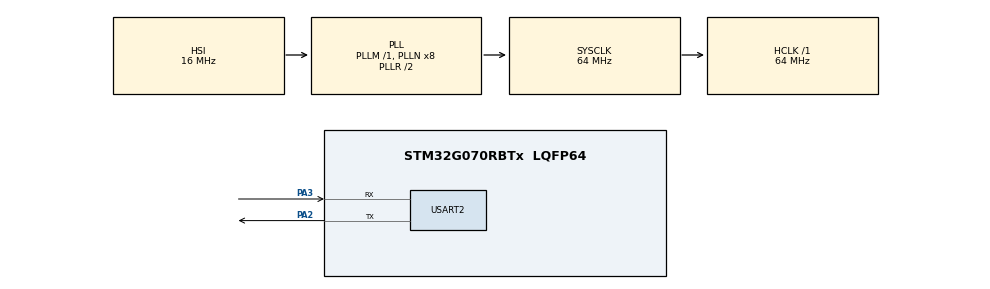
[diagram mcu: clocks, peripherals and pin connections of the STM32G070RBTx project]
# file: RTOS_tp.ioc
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FREERTOS.Tasks01=defaultTask,24,128,StartDefaultTask,Default,NULL,Dynamic,NULL,NULL
FREERTOS.configCHECK_FOR_STACK_OVERFLOW=2
FREERTOS.configTOTAL_HEAP_SIZE=12288
FREERTOS.configUSE_MALLOC_FAILED_HOOK=1
Mcu.Family=STM32G0
Mcu.Name=STM32G070RBTx
Mcu.Package=LQFP64
NVIC.TIM6_IRQn=true\:3\:0\:false\:false\:true\:false\:false\:true\:true
NVIC.TimeBase=TIM6_IRQn
NVIC.TimeBaseIP=TIM6
NVIC.USART2_IRQn=true\:3\:0\:false\:false\:true\:true\:true\:true\:true
PA2.Mode=Asynchronous
PA2.Signal=USART2_TX
PA3.Mode=Asynchronous
PA3.Signal=USART2_RX
PF0-OSC_IN\ (PF0).Mode=HSE-External-Oscillator
PF0-OSC_IN\ (PF0).Signal=RCC_OSC_IN
PF1-OSC_OUT\ (PF1).Mode=HSE-External-Oscillator
PF1-OSC_OUT\ (PF1).Signal=RCC_OSC_OUT
ProjectManager.HeapSize=0x200
ProjectManager.StackSize=0x400
ProjectManager.TargetToolchain=STM32CubeIDE
RCC.ADCFreq_Value=64000000
RCC.AHBFreq_Value=64000000
RCC.CortexFreq_Value=64000000
RCC.EXTERNAL_CLOCK_VALUE=12288000
RCC.HCLKFreq_Value=64000000
RCC.HSE_VALUE=8000000
RCC.HSI_VALUE=16000000
RCC.SYSCLKFreq_VALUE=64000000
RCC.SYSCLKSource=RCC_SYSCLKSOURCE_PLLCLK
RCC.VCOOutputFreq_Value=128000000
USART2.VirtualMode-Asynchronous=VM_ASYNC
VP_FREERTOS_VS_CMSIS_V2.Mode=CMSIS_V2
VP_SYS_VS_tim6.Mode=TIM6
board=NUCLEO-G070RB

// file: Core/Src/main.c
/* USER CODE BEGIN Header */
/**
  ******************************************************************************
  * @file           : main.c
  * @brief          : Main program body
  ******************************************************************************
  * @attention
  *
  * Copyright (c) 2026 STMicroelectronics.
  * All rights reserved.
  *
  * This software is licensed under terms that can be found in the LICENSE file
  * in the root directory of this software component.
  * If no LICENSE file comes with this software, it is provided AS-IS.
  *
  ******************************************************************************
  */
/* USER CODE END Header */
#include "main.h"
#include "cmsis_os.h"

/* USER CODE BEGIN Includes */
/* USER CODE BEGIN Includes */
#include "FreeRTOS.h"
#include "task.h"
#include "queue.h"
#include "semphr.h"
#include <stdio.h>
#include <stdarg.h>
#include <string.h>
#include <stdlib.h>
#include <ctype.h>
/* USER CODE END Includes */

/* USER CODE BEGIN PTD */
/* USER CODE BEGIN PTD */
typedef enum { LED_MODE_OFF, LED_MODE_ON, LED_MODE_BLINK } LedMode_t;

typedef struct {
    LedMode_t mode;
    uint32_t  period_ms;
} LedCmd_t;

typedef struct {
    uint32_t cmds_ok;
    uint32_t cmds_err;
    uint32_t jobs_done;
} Stats_t;

typedef struct {
    const char *name;
    int (*fn)(int argc, char **argv);   /* return 0 = OK, -1 = error */
    const char *help;
} Command_t;
/* USER CODE END PTD */

/* USER CODE BEGIN PD */
/* USER CODE BEGIN PD */
#define LED_PORT        GPIOA
#define LED_PIN         GPIO_PIN_5

/* Task priorities (higher number = higher priority) */
#define PRIO_WORKER     1
#define PRIO_LED        2
#define PRIO_CMD        3

/* Stack sizes in WORDS (4 bytes) */
#define STACK_CMD       384
#define STACK_LED       128
#define STACK_WORKER    384

#define RX_QUEUE_LEN    64
#define LED_QUEUE_LEN   4
#define JOB_POOL_MAX    5      /* counting semaphore max count (N) */
#define CMD_BUF_LEN     64
#define CMD_MAX_ARGS    4
#define TX_BUF_LEN      128
#define NELEMS(a)       (sizeof(a) / sizeof((a)[0]))
/* USER CODE END PD */

UART_HandleTypeDef huart2;

/* Definitions for defaultTask */
osThreadId_t defaultTaskHandle;
const osThreadAttr_t defaultTask_attributes = {
  .name = "defaultTask",
  .priority = (osPriority_t) osPriorityNormal,
  .stack_size = 128 * 4
};
/* USER CODE BEGIN PV */
/* USER CODE BEGIN PV */
QueueHandle_t     qRxBytes;     /* used from it.c (extern) */
QueueHandle_t     qLed;
SemaphoreHandle_t mtxUart;      /* mutex: UART TX */
SemaphoreHandle_t mtxData;      /* mutex: shared stats */
SemaphoreHandle_t semTxDone;    /* binary semaphore (given from ISR) */
SemaphoreHandle_t semJobs;      /* counting semaphore (given from ISR + task) */
TaskHandle_t      hCmdTask, hLedTask, hWorkerTask;

uint8_t rx_byte;                /* single-byte buffer for HAL_UART_Receive_IT */
static Stats_t g_stats;
/* USER CODE END PV */

void SystemClock_Config(void);
static void MX_GPIO_Init(void);
static void MX_USART2_UART_Init(void);
void StartDefaultTask(void *argument);

/* USER CODE BEGIN PFP */
/* USER CODE BEGIN PFP */
void StartCmdTask(void *argument);
void StartLedTask(void *argument);
void StartWorkerTask(void *argument);
void uart_printf(const char *fmt, ...);
/* USER CODE END PFP */

int main(void)
{

  /* MCU Configuration--------------------------------------------------------*/

  /* Reset of all peripherals, Initializes the Flash interface and the Systick. */
  HAL_Init();

  /* Configure the system clock */
  SystemClock_Config();

  /* Initialize all configured peripherals */
  MX_GPIO_Init();
  MX_USART2_UART_Init();
  /* USER CODE BEGIN 2 */
  /* USER CODE BEGIN 2 */
  HAL_UART_Transmit(&huart2, (uint8_t *)"hello\r\n", 7, 100);
  qRxBytes  = xQueueCreate(RX_QUEUE_LEN, sizeof(uint8_t));
  qLed      = xQueueCreate(LED_QUEUE_LEN, sizeof(LedCmd_t));
  mtxUart   = xSemaphoreCreateMutex();
  mtxData   = xSemaphoreCreateMutex();
  semTxDone = xSemaphoreCreateBinary();                 /* starts empty */
  semJobs   = xSemaphoreCreateCounting(JOB_POOL_MAX, 0); /* max N, initial 0 */

  if (!qRxBytes || !qLed || !mtxUart || !mtxData || !semTxDone || !semJobs)
      Error_Handler();

  if (xTaskCreate(StartCmdTask,    "cmd",    STACK_CMD,    NULL, PRIO_CMD,    &hCmdTask)    != pdPASS) Error_Handler();
  if (xTaskCreate(StartLedTask,    "led",    STACK_LED,    NULL, PRIO_LED,    &hLedTask)    != pdPASS) Error_Handler();
  if (xTaskCreate(StartWorkerTask, "worker", STACK_WORKER, NULL, PRIO_WORKER, &hWorkerTask) != pdPASS) Error_Handler();

  HAL_UART_Receive_IT(&huart2, &rx_byte, 1);   /* start RX interrupt chain */

  vTaskStartScheduler();                        /* never returns */
  Error_Handler();
  /* USER CODE END 2 */

  /* Init scheduler */
  osKernelInitialize();

  /* Create the thread(s) */
  /* creation of defaultTask */
  defaultTaskHandle = osThreadNew(StartDefaultTask, NULL, &defaultTask_attributes);

  /* Start scheduler */
  osKernelStart();

  /* We should never get here as control is now taken by the scheduler */

  /* Infinite loop */
  while (1)
  {

  }
}

void SystemClock_Config(void)
{
  RCC_OscInitTypeDef RCC_OscInitStruct = {0};
  RCC_ClkInitTypeDef RCC_ClkInitStruct = {0};

  /** Configure the main internal regulator output voltage
  */
  HAL_PWREx_ControlVoltageScaling(PWR_REGULATOR_VOLTAGE_SCALE1);

  /** Initializes the RCC Oscillators according to the specified parameters
  * in the RCC_OscInitTypeDef structure.
  */
  RCC_OscInitStruct.OscillatorType = RCC_OSCILLATORTYPE_HSI;
  RCC_OscInitStruct.HSIState = RCC_HSI_ON;
  RCC_OscInitStruct.HSIDiv = RCC_HSI_DIV1;
  RCC_OscInitStruct.HSICalibrationValue = RCC_HSICALIBRATION_DEFAULT;
  RCC_OscInitStruct.PLL.PLLState = RCC_PLL_ON;
  RCC_OscInitStruct.PLL.PLLSource = RCC_PLLSOURCE_HSI;
  RCC_OscInitStruct.PLL.PLLM = RCC_PLLM_DIV1;
  RCC_OscInitStruct.PLL.PLLN = 8;
  RCC_OscInitStruct.PLL.PLLP = RCC_PLLP_DIV2;
  RCC_OscInitStruct.PLL.PLLR = RCC_PLLR_DIV2;
  if (HAL_RCC_OscConfig(&RCC_OscInitStruct) != HAL_OK)
  {
    Error_Handler();
  }

  /** Initializes the CPU, AHB and APB buses clocks
  */
  RCC_ClkInitStruct.ClockType = RCC_CLOCKTYPE_HCLK|RCC_CLOCKTYPE_SYSCLK
                              |RCC_CLOCKTYPE_PCLK1;
  RCC_ClkInitStruct.SYSCLKSource = RCC_SYSCLKSOURCE_PLLCLK;
  RCC_ClkInitStruct.AHBCLKDivider = RCC_SYSCLK_DIV1;
  RCC_ClkInitStruct.APB1CLKDivider = RCC_HCLK_DIV1;

  if (HAL_RCC_ClockConfig(&RCC_ClkInitStruct, FLASH_LATENCY_2) != HAL_OK)
  {
    Error_Handler();
  }
}

static void MX_USART2_UART_Init(void)
{

  huart2.Instance = USART2;
  huart2.Init.BaudRate = 115200;
  huart2.Init.WordLength = UART_WORDLENGTH_8B;
  huart2.Init.StopBits = UART_STOPBITS_1;
  huart2.Init.Parity = UART_PARITY_NONE;
  huart2.Init.Mode = UART_MODE_TX_RX;
  huart2.Init.HwFlowCtl = UART_HWCONTROL_NONE;
  huart2.Init.OverSampling = UART_OVERSAMPLING_16;
  huart2.Init.OneBitSampling = UART_ONE_BIT_SAMPLE_DISABLE;
  huart2.Init.ClockPrescaler = UART_PRESCALER_DIV1;
  huart2.AdvancedInit.AdvFeatureInit = UART_ADVFEATURE_NO_INIT;
  if (HAL_UART_Init(&huart2) != HAL_OK)
  {
    Error_Handler();
  }
  if (HAL_UARTEx_SetTxFifoThreshold(&huart2, UART_TXFIFO_THRESHOLD_1_8) != HAL_OK)
  {
    Error_Handler();
  }
  if (HAL_UARTEx_SetRxFifoThreshold(&huart2, UART_RXFIFO_THRESHOLD_1_8) != HAL_OK)
  {
    Error_Handler();
  }
  if (HAL_UARTEx_DisableFifoMode(&huart2) != HAL_OK)
  {
    Error_Handler();
  }

}

static void MX_GPIO_Init(void)
{

  /* GPIO Ports Clock Enable */
  __HAL_RCC_GPIOF_CLK_ENABLE();
  __HAL_RCC_GPIOA_CLK_ENABLE();

  /* USER CODE BEGIN MX_GPIO_Init_2 */
  GPIO_InitTypeDef gpio = {0};
  gpio.Pin   = GPIO_PIN_5;
  gpio.Mode  = GPIO_MODE_OUTPUT_PP;             /* push-pull output */
  gpio.Pull  = GPIO_NOPULL;
  gpio.Speed = GPIO_SPEED_FREQ_LOW;
  HAL_GPIO_Init(GPIOA, &gpio);

  HAL_GPIO_WritePin(GPIOA, GPIO_PIN_5, GPIO_PIN_SET);
  /* USER CODE END MX_GPIO_Init_2 */
}

/* USER CODE BEGIN 4 */
/* USER CODE BEGIN 4 */
/* ---------- Thread-safe UART printf (mutex + binary semaphore) ---------- */
void uart_printf(const char *fmt, ...)
{
    static char buf[TX_BUF_LEN];            /* protected by mtxUart */

    if (xSemaphoreTake(mtxUart, pdMS_TO_TICKS(200)) != pdTRUE) return;

    va_list ap;
    va_start(ap, fmt);
    int n = vsnprintf(buf, sizeof(buf), fmt, ap);
    va_end(ap);

    if (n > 0) {
        if (n >= (int)sizeof(buf)) n = sizeof(buf) - 1;
        xSemaphoreTake(semTxDone, 0);       /* clear any stale signal */
        if (HAL_UART_Transmit_IT(&huart2, (uint8_t *)buf, (uint16_t)n) == HAL_OK) {
            /* block until HAL_UART_TxCpltCallback (it.c) gives the semaphore */
            xSemaphoreTake(semTxDone, pdMS_TO_TICKS(200));
        }
    }
    xSemaphoreGive(mtxUart);
}

/* ---------- Shared data helper (mutex) ---------- */
static void stats_inc(uint32_t *field)
{
    if (xSemaphoreTake(mtxData, portMAX_DELAY) == pdTRUE) {
        (*field)++;
        xSemaphoreGive(mtxData);
    }
}

/* ---------- Command handlers: return 0 = OK, -1 = error ---------- */
static int cmd_help(int argc, char **argv);
static int cmd_led(int argc, char **argv);
static int cmd_job(int argc, char **argv);
static int cmd_status(int argc, char **argv);

/* To add a command: write a handler and add one line here */
static const Command_t cmdTable[] = {
    { "help",   cmd_help,   "list commands" },
    { "led",    cmd_led,    "led on|off|blink [period_ms]" },
    { "job",    cmd_job,    "job [n]  - queue n jobs for the worker" },
    { "status", cmd_status, "show stats and stack usage" },
};

static int cmd_help(int argc, char **argv)
{
    (void)argc; (void)argv;
    for (size_t i = 0; i < NELEMS(cmdTable); i++)
        uart_printf("  %-7s %s\r\n", cmdTable[i].name, cmdTable[i].help);
    return 0;
}

static int cmd_led(int argc, char **argv)
{
    LedCmd_t m = { LED_MODE_OFF, 0 };

    if (argc < 2) goto usage;

    if      (strcmp(argv[1], "on")  == 0) m.mode = LED_MODE_ON;
    else if (strcmp(argv[1], "off") == 0) m.mode = LED_MODE_OFF;
    else if (strcmp(argv[1], "blink") == 0) {
        m.mode = LED_MODE_BLINK;
        m.period_ms = (argc >= 3) ? strtoul(argv[2], NULL, 10) : 500;
        if (m.period_ms < 10 || m.period_ms > 10000) {
            uart_printf("period must be 10..10000 ms\r\n");
            return -1;
        }
    } else goto usage;

    if (xQueueSend(qLed, &m, pdMS_TO_TICKS(50)) != pdTRUE) {
        uart_printf("ERR: LED queue full\r\n");
        return -1;
    }
    uart_printf("OK\r\n");
    return 0;

usage:
    uart_printf("usage: led on|off|blink [period_ms]\r\n");
    return -1;
}

static int cmd_job(int argc, char **argv)
{
    uint32_t n = (argc >= 2) ? strtoul(argv[1], NULL, 10) : 1;
    uint32_t queued = 0;

    while (queued < n && xSemaphoreGive(semJobs) == pdTRUE) queued++;

    uart_printf("queued %lu/%lu job(s)%s\r\n", (unsigned long)queued,
                (unsigned long)n, (queued < n) ? " (pool full)" : "");
    return (queued == n) ? 0 : -1;
}

static int cmd_status(int argc, char **argv)
{
    (void)argc; (void)argv;
    Stats_t s;

    xSemaphoreTake(mtxData, portMAX_DELAY);
    s = g_stats;
    xSemaphoreGive(mtxData);

    uart_printf("uptime : %lu ms\r\n", (unsigned long)(xTaskGetTickCount() * portTICK_PERIOD_MS));
    uart_printf("cmds   : ok=%lu err=%lu\r\n", (unsigned long)s.cmds_ok, (unsigned long)s.cmds_err);
    uart_printf("jobs   : done=%lu pending=%lu\r\n", (unsigned long)s.jobs_done,
                (unsigned long)uxSemaphoreGetCount(semJobs));
    uart_printf("stack free (words): cmd=%lu led=%lu worker=%lu\r\n",
                (unsigned long)uxTaskGetStackHighWaterMark(hCmdTask),
                (unsigned long)uxTaskGetStackHighWaterMark(hLedTask),
                (unsigned long)uxTaskGetStackHighWaterMark(hWorkerTask));
    return 0;
}

/* ---------- Command extraction + dispatch ---------- */
static void Cmd_Process(char *line)
{
    char *argv[CMD_MAX_ARGS];
    char *save = NULL;
    int   argc = 0;

    /* split on spaces; strtok_r is re-entrant, so it is safe with RTOS */
    for (char *t = strtok_r(line, " \t", &save);
         t && argc < CMD_MAX_ARGS;
         t = strtok_r(NULL, " \t", &save))
    {
        for (char *p = t; *p; p++) *p = (char)tolower((unsigned char)*p);
        argv[argc++] = t;
    }
    if (argc == 0) return;

    for (size_t i = 0; i < NELEMS(cmdTable); i++) {
        if (strcmp(argv[0], cmdTable[i].name) == 0) {
            if (cmdTable[i].fn(argc, argv) == 0) stats_inc(&g_stats.cmds_ok);
            else                                 stats_inc(&g_stats.cmds_err);
            return;
        }
    }
    uart_printf("unknown command '%s' (try: help)\r\n", argv[0]);
    stats_inc(&g_stats.cmds_err);
}

/* ---------- TASK 1: command task (prio 3) ---------- */
void StartCmdTask(void *argument)
{
    (void)argument;
    char    line[CMD_BUF_LEN];
    uint8_t idx = 0;
    uint8_t c;

    uart_printf("\r\n== STM32G070 + FreeRTOS ready, type 'help' ==\r\n> ");

    for (;;)
    {
        /* sleeps here until the RX ISR pushes a byte */
        if (xQueueReceive(qRxBytes, &c, portMAX_DELAY) != pdTRUE) continue;

        if (c == '\r' || c == '\n') {
            if (idx > 0) {
                line[idx] = '\0';
                uart_printf("\r\n");
                Cmd_Process(line);
                idx = 0;
                uart_printf("> ");
            }
        }
        else if (c == 0x7F || c == '\b') {          /* backspace */
            if (idx > 0) { idx--; uart_printf("\b \b"); }
        }
        else if (idx < CMD_BUF_LEN - 1) {           /* extra chars are dropped */
            line[idx++] = (char)c;
            uart_printf("%c", c);                   /* echo */
        }
    }
}

/* ---------- TASK 2: LED task (prio 2) ---------- */
void StartLedTask(void *argument)
{
    (void)argument;
    LedCmd_t  cmd;
    LedMode_t mode   = LED_MODE_BLINK;
    uint32_t  period = 500;

    for (;;)
    {
        /* the queue timeout doubles as the blink timer */
        TickType_t wait = (mode == LED_MODE_BLINK) ? pdMS_TO_TICKS(period) : portMAX_DELAY;

        if (xQueueReceive(qLed, &cmd, wait) == pdTRUE) {
            mode = cmd.mode;
            if (mode == LED_MODE_BLINK) period = cmd.period_ms;
            if (mode == LED_MODE_ON)  HAL_GPIO_WritePin(LED_PORT, LED_PIN, GPIO_PIN_SET);
            if (mode == LED_MODE_OFF) HAL_GPIO_WritePin(LED_PORT, LED_PIN, GPIO_PIN_RESET);
        } else {
            HAL_GPIO_TogglePin(LED_PORT, LED_PIN);   /* timeout -> toggle */
        }
    }
}

/* ---------- TASK 3: worker task (prio 1, lowest) ---------- */
void StartWorkerTask(void *argument)
{
    (void)argument;

    for (;;)
    {
        /* blocks until a job is available (from 'job n' or button press) */
        xSemaphoreTake(semJobs, portMAX_DELAY);

        vTaskDelay(pdMS_TO_TICKS(500));              /* simulate work */

        xSemaphoreTake(mtxData, portMAX_DELAY);
        uint32_t id = ++g_stats.jobs_done;
        xSemaphoreGive(mtxData);

        uart_printf("[worker] job #%lu done\r\n", (unsigned long)id);
    }
}

/* USER CODE END 4 */

void StartDefaultTask(void *argument)
{
  for(;;)
  {
    osDelay(1);
  }
}

void HAL_TIM_PeriodElapsedCallback(TIM_HandleTypeDef *htim)
{
  if (htim->Instance == TIM6)
  {
    HAL_IncTick();
  }
}

void Error_Handler(void)
{
  __disable_irq();
  while (1)
  {
  }
}

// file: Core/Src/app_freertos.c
/* USER CODE BEGIN Header */
/**
  ******************************************************************************
  * File Name          : app_freertos.c
  * Description        : Code for freertos applications
  ******************************************************************************
  * @attention
  *
  * Copyright (c) 2026 STMicroelectronics.
  * All rights reserved.
  *
  * This software is licensed under terms that can be found in the LICENSE file
  * in the root directory of this software component.
  * If no LICENSE file comes with this software, it is provided AS-IS.
  *
  ******************************************************************************
  */
/* USER CODE END Header */

#include "FreeRTOS.h"
#include "task.h"
#include "main.h"

/* Hook prototypes */
/* USER CODE BEGIN 4 */
void vApplicationStackOverflowHook(xTaskHandle xTask, signed char *pcTaskName)
{
   /* slow blink = stack overflow */
   while (1) { HAL_GPIO_TogglePin(GPIOA, GPIO_PIN_5); for (volatile int i = 0; i < 400000; i++); }
}
/* USER CODE END 4 */

/* USER CODE BEGIN 5 */
void vApplicationMallocFailedHook(void)
{
   while (1) { HAL_GPIO_TogglePin(GPIOA, GPIO_PIN_5); for (volatile int i = 0; i < 100000; i++); }
}
/* USER CODE END 5 */
